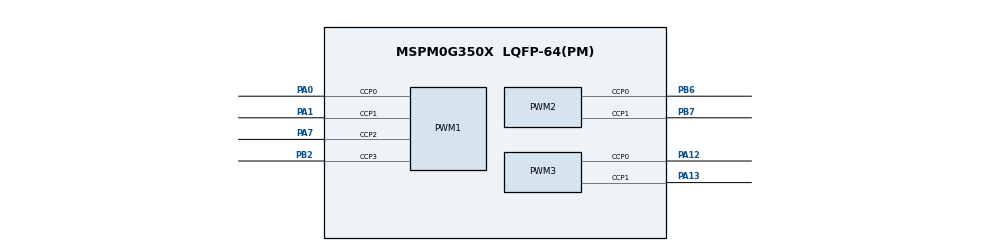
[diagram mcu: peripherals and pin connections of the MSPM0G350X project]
/**
 * @cliArgs --device "MSPM0G350X" --part "Default" --package "LQFP-64(PM)" --product "mspm0_sdk@2.02.00.05"
 * @versions {"tool":"1.21.1+3772"}
 */

/**
 * Import the modules used in this configuration.
 */
const PWM     = scripting.addModule("/ti/driverlib/PWM", {}, false);
const PWM1    = PWM.addInstance();
const PWM2    = PWM.addInstance();
const PWM3    = PWM.addInstance();
const SYSCTL  = scripting.addModule("/ti/driverlib/SYSCTL");
const SYSTICK = scripting.addModule("/ti/driverlib/SYSTICK");
const UART    = scripting.addModule("/ti/driverlib/UART", {}, false);
const UART1   = UART.addInstance();

/**
 * Write custom configuration values to the imported modules.
 */
const gate7  = system.clockTree["MFCLKGATE"];
gate7.enable = true;

PWM1.$name                      = "PWM_0";
PWM1.timerStartTimer            = true;
PWM1.ccIndex                    = [0,1,2,3];
PWM1.pwmMode                    = "EDGE_ALIGN_UP";
PWM1.timerCount                 = 3200;
PWM1.peripheral.$assign         = "TIMA0";
PWM1.peripheral.ccp0Pin.$assign = "PA0";
PWM1.peripheral.ccp1Pin.$assign = "PA1";
PWM1.peripheral.ccp2Pin.$assign = "PA7";
PWM1.peripheral.ccp3Pin.$assign = "PB2";
PWM1.PWM_CHANNEL_0.$name        = "ti_driverlib_pwm_PWMTimerCC0";
PWM1.PWM_CHANNEL_0.initVal      = "HIGH";
PWM1.PWM_CHANNEL_0.ccValue      = 3200;
PWM1.PWM_CHANNEL_1.$name        = "ti_driverlib_pwm_PWMTimerCC1";
PWM1.PWM_CHANNEL_1.initVal      = "HIGH";
PWM1.PWM_CHANNEL_1.ccValue      = 3200;
PWM1.ccp0PinConfig.$name        = "ti_driverlib_gpio_GPIOPinGeneric2";
PWM1.ccp1PinConfig.$name        = "ti_driverlib_gpio_GPIOPinGeneric3";
PWM1.PWM_CHANNEL_2.$name        = "ti_driverlib_pwm_PWMTimerCC2";
PWM1.PWM_CHANNEL_2.initVal      = "HIGH";
PWM1.PWM_CHANNEL_2.ccValue      = 3200;
PWM1.PWM_CHANNEL_3.$name        = "ti_driverlib_pwm_PWMTimerCC3";
PWM1.PWM_CHANNEL_3.initVal      = "HIGH";
PWM1.PWM_CHANNEL_3.ccValue      = 3200;
PWM1.ccp2PinConfig.$name        = "ti_driverlib_gpio_GPIOPinGeneric4";
PWM1.ccp3PinConfig.$name        = "ti_driverlib_gpio_GPIOPinGeneric5";

const Board = scripting.addModule("/ti/driverlib/Board", {}, false);

PWM2.$name                      = "PWM_1";
PWM2.pwmMode                    = "EDGE_ALIGN_UP";
PWM2.timerCount                 = 3200;
PWM2.timerStartTimer            = true;
PWM2.peripheral.$assign         = "TIMG6";
PWM2.peripheral.ccp0Pin.$assign = "PB6";
PWM2.peripheral.ccp1Pin.$assign = "PB7";
PWM2.PWM_CHANNEL_0.$name        = "ti_driverlib_pwm_PWMTimerCC4";
PWM2.PWM_CHANNEL_0.initVal      = "HIGH";
PWM2.PWM_CHANNEL_0.ccValue      = 3200;
PWM2.PWM_CHANNEL_1.$name        = "ti_driverlib_pwm_PWMTimerCC5";
PWM2.PWM_CHANNEL_1.initVal      = "HIGH";
PWM2.PWM_CHANNEL_1.ccValue      = 3200;
PWM2.ccp0PinConfig.$name        = "ti_driverlib_gpio_GPIOPinGeneric6";
PWM2.ccp1PinConfig.$name        = "ti_driverlib_gpio_GPIOPinGeneric7";

PWM3.$name                      = "PWM_2";
PWM3.timerCount                 = 3200;
PWM3.timerStartTimer            = true;
PWM3.pwmMode                    = "EDGE_ALIGN_UP";
PWM3.peripheral.$assign         = "TIMG0";
PWM3.peripheral.ccp0Pin.$assign = "PA12";
PWM3.peripheral.ccp1Pin.$assign = "PA13";
PWM3.PWM_CHANNEL_0.$name        = "ti_driverlib_pwm_PWMTimerCC6";
PWM3.PWM_CHANNEL_0.initVal      = "HIGH";
PWM3.PWM_CHANNEL_0.ccValue      = 3200;
PWM3.PWM_CHANNEL_1.$name        = "ti_driverlib_pwm_PWMTimerCC7";
PWM3.PWM_CHANNEL_1.initVal      = "HIGH";
PWM3.PWM_CHANNEL_1.ccValue      = 3200;
PWM3.ccp0PinConfig.$name        = "ti_driverlib_gpio_GPIOPinGeneric8";
PWM3.ccp1PinConfig.$name        = "ti_driverlib_gpio_GPIOPinGeneric9";

SYSCTL.forceDefaultClkConfig = true;
SYSCTL.clockTreeEn           = true;

SYSTICK.periodEnable      = true;
SYSTICK.systickEnable     = true;
SYSTICK.interruptPriority = "0";
SYSTICK.period            = 32;

UART1.$name             = "UART_0";
UART1.uartClkSrc        = "MFCLK";
UART1.enabledInterrupts = ["RX"];
UART1.txPinConfig.$name = "ti_driverlib_gpio_GPIOPinGeneric0";
UART1.rxPinConfig.$name = "ti_driverlib_gpio_GPIOPinGeneric1";

/**
 * Pinmux solution for unlocked pins/peripherals. This ensures that minor changes to the automatic solver in a future
 * version of the tool will not impact the pinmux you originally saw.  These lines can be completely deleted in order to
 * re-solve from scratch.
 */
Board.peripheral.$suggestSolution          = "DEBUGSS";
Board.peripheral.swclkPin.$suggestSolution = "PA20";
Board.peripheral.swdioPin.$suggestSolution = "PA19";
UART1.peripheral.$suggestSolution          = "UART0";
UART1.peripheral.rxPin.$suggestSolution    = "PA11";
UART1.peripheral.txPin.$suggestSolution    = "PA10";
